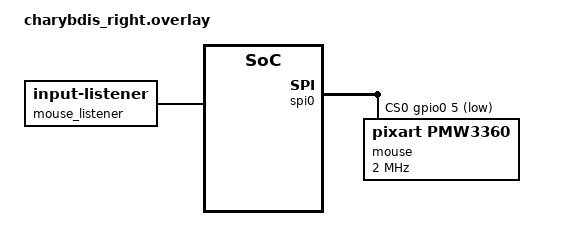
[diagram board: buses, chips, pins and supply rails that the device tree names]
#include "charybdis.dtsi" // The shared dtsi file is included in the overlay
#include "charybdis_left_pinctrl.dtsi"
#include "charybdis_right_pinctrl.dtsi"

&default_transform { // Offset of 6 because the left side has 6 columns
    col-offset = <6>;
};

// Label of the kscan node in the dtsi
&kscan0 {
    col-gpios
        = <&pro_micro 19 GPIO_ACTIVE_HIGH>
        , <&pro_micro 18 GPIO_ACTIVE_HIGH>
        , <&pro_micro 15 GPIO_ACTIVE_HIGH>
        , <&pro_micro 14 GPIO_ACTIVE_HIGH>
        , <&pro_micro 16 GPIO_ACTIVE_HIGH>
        , <&pro_micro 10 GPIO_ACTIVE_HIGH>
        ;
};

&spi0 {
	status = "okay";
	cs-gpios = <&gpio0 5 GPIO_ACTIVE_LOW>;
	mouse: mouse@0 {
		compatible = "pixart,pmw3360";
		status = "okay";
		reg = <0>;
		spi-max-frequency = <2000000>;

		// pmw3360 driver parameters
        // Removed in order to run in polled mode, also I don't have a free gpio-pin..
		// irq-gpios = <&gpio0 20 (GPIO_ACTIVE_LOW | GPIO_PULL_UP)>;
		cpi = <600>;
		rotate-90;
	};
};

/{
mouse_listener {
		compatible = "zmk,input-listener";
		device = <&mouse>;
	};
};

